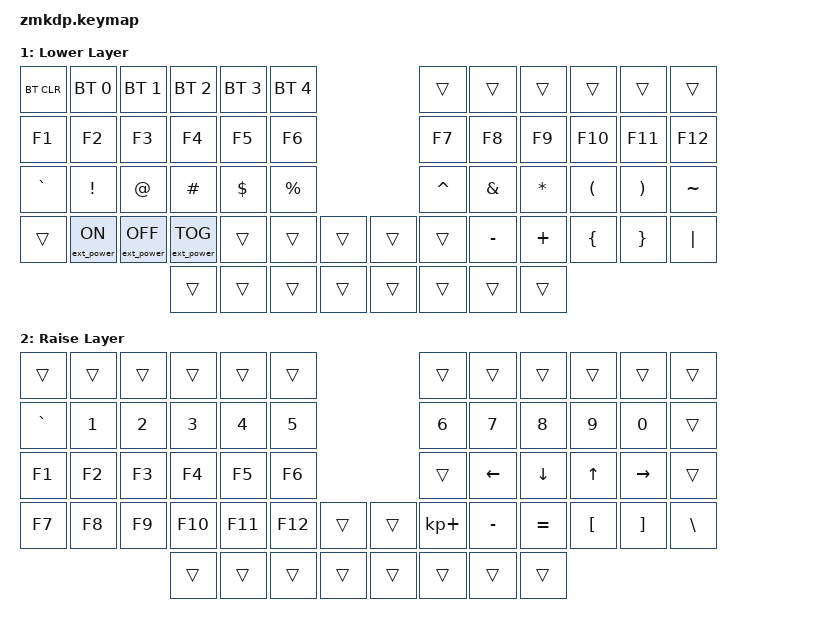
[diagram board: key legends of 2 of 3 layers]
/*
 * Copyright (c) 2020 The ZMK Contributors
 *
 * SPDX-License-Identifier: MIT
 */

#include <behaviors.dtsi>
#include <dt-bindings/zmk/keys.h>
#include <dt-bindings/zmk/bt.h>
#include <dt-bindings/zmk/ext_power.h>
#include <dt-bindings/zmk/rgb.h>

    
/ {
    keymap {
        compatible = "zmk,keymap";

        default_layer {
            display-name = "Default Layer";
// ------------------------------------------------------------------------------------------------------------
// |  ESC  |  1  |  2  |  3   |  4   |  5   |  5   |                                   |  6   |  6   |  7    |  8    |  9   |   0   |   `   |                                                        |      |      |       |       |
// |  TAB  |  Q  |  W  |  E   |  R   |  T   |  5   |                                   |  6   |  Y   |  U    |  I    |  O   |   P   |   -   |                                                        |      |      |       |       |
// |  CTRL |  A  |  S  |  D   |  F   |  G   |  5   |                                   |  6   |  H   |  J    |  K    |  L   |   ;   |   '   |                                                        |      |      |       |       |
// | SHIFT |  Z  |  X  |  C   |  V   |  B   |  5   |                                   |  6   |  N   |  M    |  ,    |  .   |   /   | SHIFT |                                                        |      |      |       |       |
//               | ALT | GUI  | LOWER|  5   |  SPACE |                                 |  6   | ENTER |  5   | RAISE| BSPC  | GUI   |
            bindings = <
&kp ESC    &kp N1    &kp N2    &kp N3    &kp N4    &kp N5    &kp LEFT                  &kp LEFT    &kp N6    &kp N7    &kp N8    &kp N9    &kp N0    &kp GRAVE                             &trans    &trans    &trans    &trans
&kp TAB    &kp Q     &kp W     &kp E     &kp R     &kp T     &kp DOWN                  &kp DOWN    &kp Y     &kp U     &kp I     &kp O     &kp P     &kp MINUS                             &trans    &trans    &trans    &trans
&kp LCTRL  &kp A     &kp S     &kp D     &kp F     &kp G     &kp UP                    &kp UP      &kp H     &kp J     &kp K     &kp L     &kp SEMI  &kp SQT                               &trans    &trans    &trans    &trans         
&kp LSHFT  &kp Z     &kp X     &kp C     &kp V     &kp B     &kp RIGHT                 &kp RIGHT   &kp N     &kp M     &kp COMMA &kp DOT   &kp FSLH  &kp RSHFT                             &trans    &trans    &trans    &trans
           &kp LALT   &kp LGUI  &mo 1    &trans    &kp SPACE &trans               &trans &kp RET  &mo 2  &kp BSPC &kp RGUI &kp RBKT                                                &trans    &trans    &trans    &trans 
                                               
            >;

            sensor-bindings = <&inc_dec_kp C_VOL_UP C_VOL_DN>;
        };


        lower_layer {
            display-name = "Lower Layer";
// ------------------------------------------------------------------------------------------------------------
// | BTCLR | BT1 | BT2 |  BT3 |  BT4 |  BT5 |                   |      |       |       |      |       |       |
// |  F1   |  F2 |  F3 |  F4  |  F5  |  F6  |                   |  F7  |  F8   |  F9   |  F10 |  F11  |  F12  |
// |   `   |  !  |  @  |  #   |  $   |  %   |                   |  ^   |  &    |  *    |  (   |   )   |   ~   |
// |       |     |     |      |      |      |        |  |       |      |  _    |  +    |  {   |   }   |  "|"  |
//                     |      |      |      |        |  |       |      |       |       |
            bindings = <
&bt BT_CLR &bt BT_SEL 0     &bt BT_SEL 1      &bt BT_SEL 2      &bt BT_SEL 3 &bt BT_SEL 4                 &trans    &trans    &trans    &trans    &trans    &trans
&kp F1     &kp F2           &kp F3            &kp F4            &kp F5       &kp F6                       &kp F7    &kp F8    &kp F9    &kp F10   &kp F11   &kp F12
&kp GRAVE  &kp EXCL         &kp AT            &kp HASH          &kp DOLLAR   &kp PRCNT                    &kp CARET &kp AMPS  &kp ASTRK &kp LPAR  &kp RPAR  &kp TILDE
&trans     &ext_power EP_ON &ext_power EP_OFF &ext_power EP_TOG &trans       &trans    &trans   &trans    &trans    &kp MINUS &kp PLUS  &kp LBRC  &kp RBRC  &kp PIPE
                                              &trans            &trans       &trans    &trans   &trans    &trans    &trans    &trans
            >;

            sensor-bindings = <&inc_dec_kp C_VOL_UP C_VOL_DN>;
        };

        raise_layer {
            display-name = "Raise Layer";
// ------------------------------------------------------------------------------------------------------------
// |       |     |     |      |      |      |                   |      |       |       |      |       |       |
// |   `   |  1  |  2  |  3   |  4   |  5   |                   |  6   |   7   |   8   |  9   |   0   |       |
// |   F1  |  F2 |  F3 |  F4  |  F5  |  F6  |                   |      |   <-  |   v   |  ^   |  ->   |       |
// |   F7  |  F8 |  F9 |  F10 |  F11 |  F12 |        |  |       |  +   |   -   |   =   |  [   |   ]   |   \   |
//                     |      |      |      |        |  |       |      |       |       |
            bindings = <
&trans    &trans &trans &trans  &trans  &trans                       &trans      &trans    &trans    &trans   &trans    &trans
&kp GRAVE &kp N1 &kp N2 &kp N3  &kp N4  &kp N5                       &kp N6      &kp N7    &kp N8    &kp N9   &kp N0    &trans
&kp F1    &kp F2 &kp F3 &kp F4  &kp F5  &kp F6                       &trans      &kp LEFT  &kp DOWN  &kp UP   &kp RIGHT &trans
&kp F7    &kp F8 &kp F9 &kp F10 &kp F11 &kp F12   &trans   &trans    &kp KP_PLUS &kp MINUS &kp EQUAL &kp LBKT &kp RBKT  &kp BSLH
                        &trans  &trans  &trans    &trans   &trans    &trans      &trans    &trans
            >;

            sensor-bindings = <&inc_dec_kp C_VOL_UP C_VOL_DN>;
        };
    };
};

&led_strip {
    chain-length = <21>;
};
